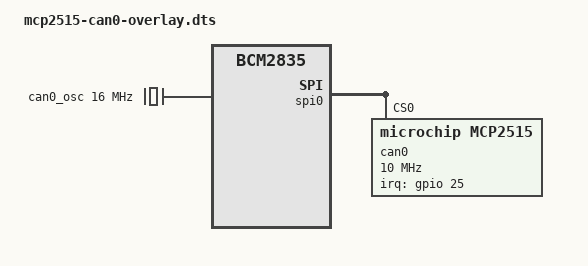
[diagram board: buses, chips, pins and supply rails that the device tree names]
// Device Tree Overlay for Microchip MCP2515 CAN controller via SPI
/dts-v1/;
/plugin/;

/ {
    compatible = "brcm,bcm2835";

    fragment@0 {
        target = <&spidev0>;
        __overlay__ {
            status = "disabled";
        };
    };

    fragment@1 {
        target = <&gpio>;
        __overlay__ {
            can0_pins: can0_pins {
                brcm,pins = <25>;
                brcm,function = <0>; /* Input */
                brcm,pull = <2>;     /* Pull-up */
            };
        };
    };

    fragment@2 {
        target-path = "clocks";
        __overlay__ {
            can0_osc: can0_osc {
                compatible = "fixed-clock";
                #clock-cells = <0>;
                clock-frequency = <16000000>; /* 16MHz Oscillator (change to 8000000 if 8MHz) */
            };
        };
    };

    fragment@3 {
        target = <&spi0>;
        __overlay__ {
            #address-cells = <1>;
            #size-cells = <0>;
            status = "okay";

            can0: mcp2515@0 {
                compatible = "microchip,mcp2515";
                reg = <0>; /* Chip Select 0 (GPIO 8) */
                pinctrl-names = "default";
                pinctrl-0 = <&can0_pins>;
                spi-max-frequency = <10000000>;
                interrupt-parent = <&gpio>;
                interrupts = <25 0x2>; /* GPIO 25, IRQ_TYPE_EDGE_FALLING */
                clocks = <&can0_osc>;
                status = "okay";
            };
        };
    };
};
